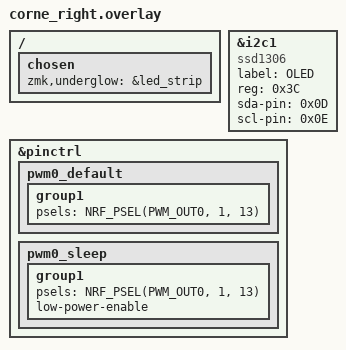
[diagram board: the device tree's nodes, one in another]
/ {
    chosen {
        zmk,underglow = &led_strip;
    };
};

&i2c1 {
    compatible = "ssd1306";
    label = "OLED";
    status = "okay";
    reg = <0x3C>;
    sda-pin = <0x0D>;
    scl-pin = <0x0E>;
};

#include <dt-bindings/led/led.h>

&pinctrl {
    // Other pinctrl definitions for other hardware
    pwm0_default: pwm0_default {
        group1 {
            psels = <NRF_PSEL(PWM_OUT0, 1, 13)>;
        };
    };
    pwm0_sleep: pwm0_sleep {
        group1 {
            psels = <NRF_PSEL(PWM_OUT0, 1, 13)>;
            low-power-enable;
        };
    };
};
